# STM32MP23_CM33 register map
File version: 1.2
CPU: CM33 r0p1, little endian, MPU, FPU, vendor SysTick, 8 interrupt priority bits
Registers are 32-bit, read-write, reset 0x0 unless marked. A register's access mark holds for its fields unless they carry their own. Offsets are from the block's base; [hi:lo] are bit positions.

## USB3DR (part 1 of 4) — USB3DR register block
Base 0x48300000
Same registers: USB3DR_S 0x58300000
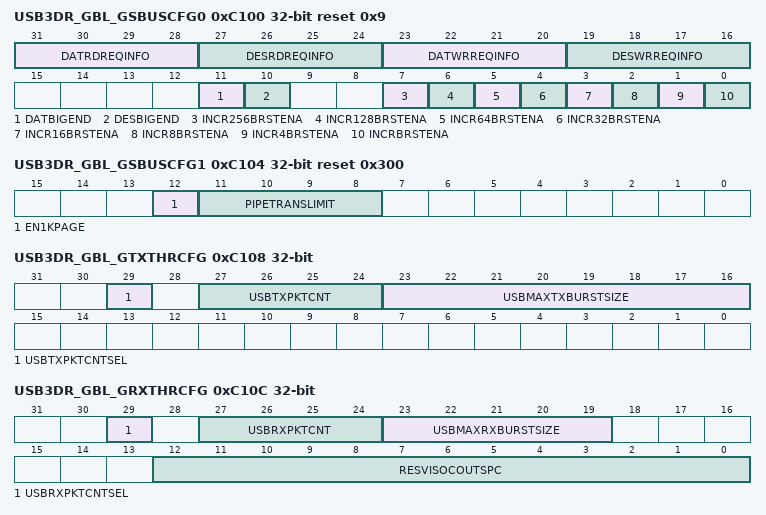
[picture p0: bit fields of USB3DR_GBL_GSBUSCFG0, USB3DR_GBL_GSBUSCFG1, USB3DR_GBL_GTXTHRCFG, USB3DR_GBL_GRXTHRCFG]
0xC100 USB3DR_GBL_GSBUSCFG0 reset 0x9 — USB3DR global device bus configuration register 0
  [31:28] DATRDREQINFO — AHB-prot/AXI-cache/OCP-ReqInfo for data read (DatRdReqInfo) Input to BUS-GM.
  [27:24] DESRDREQINFO — AHB-prot/AXI-cache/OCP-ReqInfo for descriptor read (DesRdReqInfo) Input to BUS-GM.
  [23:20] DATWRREQINFO — AHB-prot/AXI-cache/OCP-ReqInfo for data write (DatWrReqInfo) Input to BUS-GM.
  [19:16] DESWRREQINFO — AHB-prot/AXI-cache/OCP-ReqInfo for descriptor write (DesWrReqInfo). Input to BUS-GM.
  [11] DATBIGEND — Data access is big endian This bit controls the endian mode for data accesses. In big endian mode, both read and write DMA accesses for packet data use a Byte Invariant Big-Endian mode. Note: Since AXI requires byte invariant endianness, setting DescBigend and DatBigEnd to one causes an address invariant transform to be applied, which is not appropriate. See [AXI]. Hence for an AXI master (USB3DR_MBUS_TYPE=1), this bit must be set to zero.
    0=Little endian; 1=Big endian
  [10] DESBIGEND — Descriptor access is big endian This bit controls the endian mode for descriptor accesses. In big endian mode, both read and write DMA accesses for descriptors use a Byte Invariant Big-Endian mode. in the following cases, data are considered as 'embedded data' in the descriptors: Device mode: the buffer pointer of a setup TRB points to the setup TRB itself. Host mode: the immediate data (IDT) bit in a transfer TRB is set to 1. In device mode, if the system uses different endian modes for descriptor and data, software must not use 'embedded' data. In host mode, if the system uses different endian modes for data and descriptors, the controller treats 'embedded data' as descriptor (not as data) in terms of endian mode handling. If this is not the expectation of the system, the software must manipulate the 'embedded data' accordingly. Note: Since AXI requires byte invariant endianness, setting DescBigend and DatBigEnd to 1 causes an address invariant transform to be applied, which is not appropriate. See [AXI]. Hence for an AXI master (USB3DR_MBUS_TYPE=1), this bit must be set to zero.
    0=little endian; 1=big endian
  [7] INCR256BRSTENA — INCR256 burst type enable Input to BUS-GM. For the AHB/AXI configuration, if software sets this bit to 1, the AHB/AXI master uses INCR to do the 256-beat burst.
  [6] INCR128BRSTENA — INCR128 burst type enable Input to BUS-GM; For the AHB/AXI configuration, if software sets this bit to 1, the AHB/AXI master uses INCR to do the 128-beat burst.
  [5] INCR64BRSTENA — INCR64 burst type enable Input to BUS-GM. For the AHB/AXI configuration, if software sets this bit to 1, the AHB/AXI master uses INCR to do the 64-beat burst.
  [4] INCR32BRSTENA — INCR32 burst type enable Input to BUS-GM. For the AHB/AXI configuration, if software sets this bit to 1, the AHB/AXI master uses INCR to do the 32-beat burst.
  [3] INCR16BRSTENA — INCR16 burst type enable Input to BUS-GM. For the AHB/AXI configuration, if software sets this bit to 1, the AHB/AXI master uses INCR to do the 16-beat burst.
  [2] INCR8BRSTENA — INCR8 burst type enable Input to BUS-GM. For the AHB/AXI configuration, if software sets this bit to 1, the AHB/AXI master uses INCR to do the 8-beat burst.
  [1] INCR4BRSTENA — INCR4 burst type enable Input to BUS-GM. For the AXI configuration, when this bit is enabled the controller is allowed to do bursts of beat length 1, 2, 3, and 4. It is highly recommended that this bit is enabled to prevent descriptor reads and writes from being broken up into separate transfers.
  [0] INCRBRSTENA — Undefined length INCR burst type enable (INCRBrstEna) Input to BUS-GM This bit determines the set of burst lengths the master interface uses. It works in conjunction with GSBUSCFG0[7:1] (INCR256/128/64/32/16/8/4). HBURST (for AHB configurations) and ARLEN/AWLEN (for AXI configurations) do not use INCR except in case of non-aligned burst transfers. In the case of address-aligned transfers, they use only the following burst lengths: 1 4 (if GSBUSCFG0.INCR4BrstEna=1) 8 (if GSBUSCFG0.INCR8BrstEna=1) 16 (if GSBUSCFG0.INCR16BrstEna=1) 32 (if GSBUSCFG0.INCR32BrstEna=1) 64 (if GSBUSCFG0.INCR64BrstEna=1) 128 (if GSBUSCFG0.INCR128BrstEna=1) 256 (if GSBUSCFG0.INCR256BrstEna=1) Note: In case of non-address-aligned transfers, INCR may get generated at the beginning and end of the transfers to align the address boundaries, even though INCR is disabled. Note: In AHB mode, if INCRX burst mode is enabled, but none of the supported INCRx bursts bits are enabled, then the controller performs (undefined length) INCR bursts. AHB configurations: HBURST uses SINGLE or INCR of any length with handling 1KB boundary breakup. AXI configurations: ARLEN/AWLEN uses any length less than or equal to the largest-enabled burst length of INCR32/64/128/256. For cache line-aligned applications, this bit is typically set to 0 to ensure that the master interface uses only power-of-2 burst lengths (as enabled via GSBUSCFG0[7:0]).
    0=INCRX burst mode; 1=INCR (undefined length) burst mode
0xC104 USB3DR_GBL_GSBUSCFG1 reset 0x300 — USB3DR global bus configuration register 1
  [12] EN1KPAGE — 1K page boundary enable By default (this bit is disabled) the AXI breaks transfers at the 4K page boundary. When this bit is enabled, the AXI master (DMA data) breaks transfers at the 1K page boundary.
  [11:8] PIPETRANSLIMIT — AXI pipelined transfers burst request limit The field controls the number of outstanding pipelined transfer requests the AXI master pushes to the AXI slave. When the AXI master reaches this limit, it does not make any more requests on the AXI ARADDR and AWADDR buses until the associated data phases complete. This field is encoded as follows: ...
    0=1 request; 1=2 requests; 2=3 requests; 3=4 requests; 15=16 requests
0xC108 USB3DR_GBL_GTXTHRCFG — USB3DR global TX threshold control register
  [29] USBTXPKTCNTSEL — USB transmit packet count enable This field enables/disables the USB transmission multi-packet thresholding:
    0=USB transmission multi-packet thresholding is disabled. The core can start transmission on the USB after the entire (one full) packet has been fetched into the corresponding TXFIFO.; 1=USB transmission multi-packet thresholding is enabled. The core can only start transmission on the USB after USB transmit packet count amount of packets for the USB transaction (burst) are already in the corresponding TXFIFO. This mode is valid in both host and device modes. It is only used for SuperSpeed operation.
  [27:24] USBTXPKTCNT — USB transmit packet count This field specifies the number of packets that must be in the TXFIFO before the core can start transmission for the corresponding USB transaction (burst). This field is only valid when the USB transmit packet count enable field is set to one. Valid values are from 1 to 15. Note: In device mode, if device controller does not have the TRBs for the number of packets or if it cannot fetch the TRBs because of high latency or switching between other endpoints, then it does not wait for the threshold number of packets. The threshold number of packets is honored only when the TRBs are available in the controller for the number of packets before it starts the data fetch. This field must be less than or equal to the USB maximum TX burst size field.
  [23:16] USBMAXTXBURSTSIZE — USB maximum TX burst size When UsbTxPktCntSel is 1, this field specifies the maximum bulk OUT burst the core can do. When the system bus is slower than the USB, TX FIFO can underrun during a long burst. User can program a smaller value to this field to limit the TX burst size that the core can do. Host mode: It only applies to SS bulk, isochronous, and Interrupt OUT endpoints. Device mode: This value is not used in device mode, but users need to program a value when using the TX threshold feature to make sure that the value programmed in UsbTxPktCnt is less than this value. Valid values are from 1 to 16.
0xC10C USB3DR_GBL_GRXTHRCFG — USB3DR global RX threshold control register
  [29] USBRXPKTCNTSEL — USB receive packet count enable This field enables/disables the USB reception multi-packet thresholding: In device mode, Setting this bit to 1 also enables the functionality of reporting NUMP in the ACK TP based on the RX FIFO space instead of reporting a fixed NUMP derived from DCFG.NUMP for non-control endpoints. If external buffer control (EBC) feature is used, disable this mode by setting UsbRxPktCntSel to 0.
    0=The core can only start reception on the USB when the RX FIFO has space for at least one packet; 1=The core can only start reception on the USB when the RX FIFO has space for at least UsbRxPktCnt amount of packets. This mode is valid in both host and device modes. It is only used for SuperSpeed.
  [27:24] USBRXPKTCNT — USB receive packet count In host mode, this field specifies the space (in terms of number of packets) that must be available in the RX FIFO before the core can start the corresponding USB RX transaction (burst). In device mode, this field specifies the space (in terms of number of packets) that must be available in the RX FIFO before the core can send ERDY for a flow-controlled endpoint. This field is valid only when the USB receive packet count enable field is set to 1. The valid values for this field are from 1 to 15. Note: This field must be less than or equal to the USB maximum receive burst size field.
  [23:19] USBMAXRXBURSTSIZE — USB maximum receive burst size In host mode, this field specifies the maximum bulk IN burst the USB3DR can perform. When the system bus is slower than the USB, RX FIFO can overrun during a long burst. A smaller value can be programmed to this field to limit the RX burst size that the core can perform. It only applies to SS bulk, isochronous, and interrupt IN endpoints in the host mode. In device mode, this field specifies the NUMP value that is sent in ERDY for an OUT endpoint. The programmed value should not exceed the RXFIFO size. This field is valid only when UsbRxPktCntSel is one. The valid values for this field are from 1 to 16.
  [12:0] RESVISOCOUTSPC — Space reserved in RX FIFO for ISOC OUT In host mode, this field is not applicable and must be programmed to 0. In device mode, this value represents the amount of space to be reserved for ISOC OUT packets. The value to be programmed should be chosen so as to ensure that non ISOC packets are not completely dropped. If no space needs to be reserved for ISOC OUT packets, program this field to 0. This field is valid only in device mode. The maximum configurable depth of RX FIFO is 8192. Therefore, this field is 13 bits wide. The value of space reserved is in terms of USB3DR_MDWIDTH. For SS, the space reservation is always rounded off to the nearest packet boundary. Therefore, it is always recommended to program a value corresponding to MPS or its multiples. For HS/FS, the space reservation is the actual value. Note: For SS, reserve space for ISOC when the RX FIFO space can accommodate two MPS or more. Otherwise, this may result in degraded performance for non-ISOC packets. If the space is entirely allocated for ISOC, the non-ISOC packets are completely dropped.
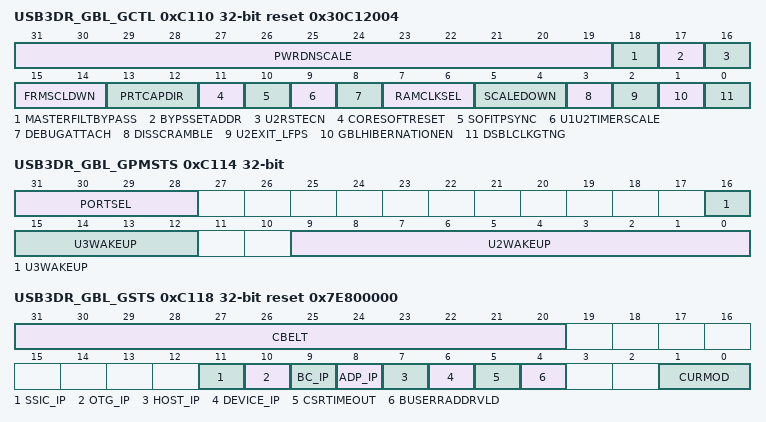
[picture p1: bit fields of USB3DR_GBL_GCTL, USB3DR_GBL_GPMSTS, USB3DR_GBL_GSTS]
0xC110 USB3DR_GBL_GCTL reset 0x30C12004 — USB3DR global control register
  [31:19] PWRDNSCALE — Power down scale (PwrDnScale) The USB3 suspend_clk input replaces pipe3_rx_pclk as a clock source to a small part of the USB3 core that operates when the SS PHY is in its lowest power (P3) state, and therefore does not provide a clock. The power down scale field specifies how many suspend_clk periods fit into a 16kHz clock period. When performing the division, round up the remainder. For example, when using an 8-bit/16-bit/32-bit PHY and 25MHz suspend clock, Power Down scale=25000kHz/16kHz=1563 (rounded up) Minimum suspend clock frequency is 32kHz Note: Maximum suspend clock frequency is 125MHz The LTSSM uses suspend clock for 12ms and 100ms timers during suspend mode. According to the USB 3.0 specification, the accuracy on these timers is 0% to +50%. 12ms + 0~+50% accuracy=18ms (Range is 12ms - 18ms) 100ms + 0~+50% accuracy=150ms (Range is 100ms - 150ms). The suspend clock accuracy requirement is: (12,000/62.5) (GCTL[31:19]) actual suspend_clk_period, must be between 12,000 and 18,000 (100,0000/62.5) (GCTL[31:19]) actual suspend_clk_period, must be between 100,000 and 150,000 For example, if suspend_clk frequency varies from 7.5MHz to 10.5MHz, then the value that needs to be programmed is: Power down scale=10500/16=657 (rounded up integer).
  [18] MASTERFILTBYPASS — Master filter bypass
    0=Filters enabled; 1=All VBUS debouncing filters are bypassed, regardless of the USB3DR_EN_BUS_FILTERS value. The double synchronizers to mac_clk preceding the filters are also bypassed.
  [17] BYPSSETADDR — Bypass SetAddress in Device mode When BYPSSETADDR bit is set, the device core uses the value in the DCFG[DevAddr] bits directly for comparing the device address in the tokens. This feature can be used in simulation to avoid sending an actual SET ADDRESS control transfer on the USB, and make the device core respond to a new address. When the xHCI debug capability is enabled and this bit is set, the debug target immediately enters the configured state without requiring the debug Host to send a SetAddress or SetConfig request. Note: This bit can be set for simulation purposes only. In the actual hardware, this bit must be set to 0.
  [16] U2RSTECN — U2RSTECN If the SuperSpeed connection fails during POLL or LMP exchange, the device connects at non-SS mode. If this bit is set, then the device attempts three more times to connect at SS, even if it previously failed to operate in SS mode. For each attempt, the device checks receiver termination eight times. From 2.60a release, this bit controls whether to check for RX.Detect eight times or one time for every attempt. The device controller on USB 2.0 reset checks for receiver termination eight times per attempt if this bit is set to zero, or only once per attempt if the bit is set to one. Note: This bit is applicable only in Device mode.
  [15:14] FRMSCLDWN — FRMSCLDWN This field scales down device view of a SOF/USOF/ITP duration. When xHCI debug capability is enabled, this field also scales down the MaxPacketSize of the IN and OUT bulk endpoint to allow more traffic during simulation. It can only be changed from a non-zero value during simulation.
    1=B_0x1_SS_HS_MODE_ (implements interval to be 62.5 us); 0=B_0x0_SS_HS_MODE_ (implements interval to be 125 us)
  [13:12] PRTCAPDIR — Port capability direction (PrtCapDir) When USB3DR_EN_OTG is 0, then the core acts as a DRD. When USB3DR_EN_OTG is 1: If PrtCapDir is 0b11, it acts as an OTG 2.0 device with A-device or B-device determined by the IDDIG input, and Host or Peripheral role based on HNP. If PrtCapDir is 0b01, it acts as a DRD in Host mode. If PrtCapDir is 0b10, it acts as a DRD in Device mode. The OTG device can be programmed to enable/disable SRP and HNP by using the fields present in OCFG register. When USB3DR_EN_OTG is 2: If PrtCapDir is 0b11, it acts as an OTG 3.0 device with A-device or B-device determined by the IDDIG input, and Host or Peripheral role based on HNP/RSP. If PrtCapDir is 0b01, it acts as a DRD in Host mode. In this mode, the VBUS is driven immediately after power-on reset. When the USB3DR controller is plugged into a PC and the application configures the device later on, VBUS is driven on the USB from both sides of the cable. This may damage the PC host. If PrtCapDir is 0b10, it acts as a DRD in Device mode. The OTG device can be programmed to enable/disable SRP and HNP/RSP using the fields present in the OCFG register. Note: For static Host-only/Device-only applications, use DRD Host or DRD Device mode. The combination of GCTL.PrtCapDir=0b11 with SRP and HNP/RSP disabled is not recommended for these applications. The sequence for switching modes in DRD configuration is as follows: Switching from Device to Host: 1. Reset the controller using GCTL[11] (CoreSoftReset). 2. Set GCTL[13:12] (PrtCapDir) to 0b01 (Host mode). 3. Reset the host using USBCMD.HCRESET. 4. Initialize the Host registers. Switching from Host to Device: 1. Reset the controller using GCTL[11] (CoreSoftReset). 2. Set GCTL[13:12] (PrtCapDir) to 0b10 (Device mode). 3. Reset the device by setting DCTL[30] (CSftRst). 4. Initialize the Device registers. Programming this field with random data causes the core to keep toggling between the host mode and the device mode. Bit bash register testing is not recommended.
    1=for Host configurations; 2=for Device configurations; 3=for OTG configurations
  [11] CORESOFTRESET — Core soft reset (CoreSoftReset) Clears the interrupts and all the CSRs except the following registers: - GCTL - GUCTL - GSTS - GSNPSID - GGPIO - GUID - GUSB2PHYCFGn registers - GUSB3PIPECTLn registers - DCFG - DCTL - DEVTEN - DSTS When reseting PHYs (using GUBS3PHYCFG or GUSB3PIPECTL registers), the core must be kept in reset state until PHY clocks are stable. This controls the bus, ram, and MAC domain resets. Note: This bit is for debug purposes only. Use USBCMD.HCRESET in xHCI mode and DCTL.SoftReset in device mode for soft reset. Note: Programming this field with random data resets the internal logic of the host controller. Due to this side effect bit bash register testing is not recommended.
    0=No soft reset; 1=Soft reset to core
  [10] SOFITPSYNC — SOFITPSYNC If this bit is set to 0 operating in host mode, the core keeps the UTMI/ULPI PHY on the first port in a non-suspended state whenever there is a SuperSpeed port that is not in RX.Detect, SS.Disable and U3. If this bit is set to '1' operating in host mode, the core keeps the UTMI/ULPI PHY on the first port in a non-suspended state whenever the other non-SuperSpeed ports are not in a suspended state. This feature is useful because it saves power by suspending UTMI/ULPI when SuperSpeed only is active, and it helps resolve when the PHY does not transmit a host resume unless it is placed in suspend state. This bit must be programmed as a part of initialization at power-on reset, and must not be dynamically changed afterwards. Note: USB2PHYCFGn[6].PhySusp eventually decides to put the UTMI/ULPI PHY into suspend state. In addition, when this bit is set to 1, the core generates ITP from the ref_clk based counter. Otherwise, ITP and SOF are generated from utmi/ulpi_clk[0] based counter. To program the reference clock period inside the core, refer to GUCTL[31:22].REFCLKPER. Note: This feature is valid in Host and DRD/OTG configurations and used only in Host mode operation. Note: If this feature or the GFLADJ.GFLADJ_REFCLK_LPM_SEL is never used, the minimum frequency for the ref_clk can be as low as 32kHz. The suspend_clk (as low as 32kHz) can be connected to the ref_clk. Note: If hardware-based LPM or software-based LPM has to be enabled (PORTPMSC.HLE=1), then this feature cannot be used. Turn off this feature by setting this bit to 0 and use the GFLADJ.GFLADJ_REFCLK_LPM_SEL feature. Note: If this bit is set to 1, the GUSB2PHYCFG.U2_FREECLK_EXISTS bit and the USB3DR_FREECLK_USB2_EXIST parameter must be set to 0. Program this bit to 0 if the core is intended to be operated in USB 3.0 mode.
  [9] U1U2TIMERSCALE — Disable U1/U2 timer scaledown (U1U2TimerScale) If set to 1 along with GCTL[5:4] (ScaleDown)=0bx1, disables the scale down of U1/U2 inactive timer values. This is for simulation mode only.
  [8] DEBUGATTACH — Debug attach When this bit is set, SS link proceeds directly to the polling link state (after RUN/STOP in the DCTL register is asserted) without checking remote termination; Link LFPS polling timeout is infinite; Polling timeout during TS1 is infinite (in case link is waiting for TXEQ to finish).
  [7:6] RAMCLKSEL — RAM clock select (RAMClkSel) In Device mode, upon a USB reset and USB disconnect, the hardware clears these bits to 00. Note: In device mode, if RAMClkSel is set to 0b11 (mac2_clk), the controller internally switches the ram_clk to bus_clk when the link state changes to suspend (L2 or L3), and switches the ram_clk back to mac2_clk when the link state changes to resume or U2. Note: In host mode, if a value of 2/3 is chosen, then controller switches ram_clk between bus_clk, mac2_clk and pipe_clk, pipe_clk/2, based on the state of the U2/U3 ports. For example if only the U2 port is active and the U3 ports are suspended, then the ram_clk is swicthed to mac2_clk. When only the U3 ports are active and the U2 ports are suspended, then the core internally swicth the ram_clk to pipe3 clock and when all U2 and U3 ports are suspended, it switches the ram_clk to bus_clk. This allows decoupling the ram_clk from the bus_clk and depending on the bandwidth requirement allows the bus_clk to be run at a lower frequency than the ram_clk requirements. bus_clk frequency still cannot go below 60MHz in Host mode, and this is not verified. Note: A value of 2 can be chosen only if the pipe data width is 8 or 16 bits. In this case when the ram_clk is switched to pipe_clk, it uses pipe_clk/2 instead of pipe_clk. If a value of 3 is chosen for RAMClkSel, when ram_clk is switched to pipe_clk, then pipe_clk is used without any divider. Note: In device mode, when RAMClkSel different 0b00, the bus_clk_early frequency can be a minimum of 1 MHz. This is tested in simulation and also in hardware with Linux, Microsoftsup®/sup Windowssup®/sup 8, and MCCI Windowssup®/sup 7 host drivers. Only control and non-periodic transfers are supported when bus_clk is 1 MHz. For periodic applications, the bus_clk_early minimum frequency is higher depending on the application and device bus. Even though 1 MHz has been tested with standard host drivers, Synopsys recommends 5 MHz minimum for ASIC designs to provide a margin or at least have a backup option to increase the bus_clk frequency to 5 MHz if needed. Programming this field with random data causes side effect. Bit bash register testing is not recommended.
    0=Bus clock; 1=Pipe clock (only used in Device mode); 2=In Device mode, pipe/2 clock. In Host mode, controller switches ram_clk between pipe/2 clock, mac2_clk and bus_clk based on the status of the U2/U3 ports; 3=In device mode, selects mac2_clk as ram_clk (when 8-bit UTMI or ULPI used, not supported in 16-bit UTMI mode). In Host mode, controller switches ram_clk between pipe_clk, mac2_clk and bus_clk based on the status of the U2/U3 ports.
  [5:4] SCALEDOWN — Scale-down mode (ScaleDown) When scale-down mode is enabled for simulation, the core uses scaled-down timing values, resulting in faster simulations. When scale-down mode is disabled, actual timing values are used. This is required for hardware operation. Number of TxEq training sequences reduce to 8 LFPS polling burst time reduce to 256ns LFPS warm reset receive reduce to 30 us.
    0=B_0x0_HS_FS_LS_MODES (Disables all scale-downs. Actual timing values are used.); 1=B_0x1_HS_FS_LS_MODES (Enables scale-down of all timing values except Device mode suspend and resume. These include speed enumeration, HNP/SRP, and Host mode suspend and resume.); 2=B_0x2_HS_FS_LS_MODES (Enables scale-down of Device mode suspend and resume timing values only.); 3=B_0x3_HS_FS_LS_MODES (Enables bit 0 and bit 1 scale-down timing values.)
  [3] DISSCRAMBLE — Disable scrambling (DisScramble) Transmit request to link partner on next transition to recovery or polling.
  [2] U2EXIT_LFPS — U2EXIT_LFPS If this bit is, This bit is added to improve interoperability with a third-party host/device controller. This host/device controller in U2 state while performing receiver detection generates an LFPS glitch of about 4ms duration. This causes the host/device to exit from U2 state because the LFPS filter value is 248ns. With the new functionality enabled, the host/device can stay in U2 while ignoring this glitch from the host/device controller. This bit is applicable for both host and device controller. This bit is added to improve interoperability with a third party host controller. This host controller in U2 state while performing receiver detection generates an LFPS glitch of about 4ms duration. This causes the device to exit from U2 state because the LFPS filter value is 248ns. With the new functionality enabled, the device can stay in U2 while ignoring this glitch from the host controller.
    0=the link treats 248ns LFPS as a valid U2 exit; 1=the link waits for 8 us of LFPS before it detects a valid U2 exit
  [1] GBLHIBERNATIONEN ro — GblHibernationEn This bit enables hibernation at the global level. If hibernation is not enabled through this bit, the PMU immediately accepts the D0 → D3 and D3 → D0 power state change requests, but does not save or restore any core state. In addition, the PMUs never drive the PHY interfaces and let the core continue to drive the PHY interfaces.
  [0] DSBLCLKGTNG — Disable clock gating (DsblClkGtng) This bit is set to 1 and the core is in Low Power mode, internal clock gating is disabled. This bit can be set to 1 after power-on reset.
0xC114 USB3DR_GBL_GPMSTS (reset mask 0xFFE0C00) — USB3DR global power management status register
  [31:28] PORTSEL wo — Global power management status register, PortSel This field selects the port number.
  [16:12] U3WAKEUP ro — U3Wakeup This field gives the following USB 3.0 port wakeup conditions: xxxx1: Overcurrent detected xxx1x: Resume detected xx1xx: Connect detected x1xxx: Disconnect detected 1xxxx: Last connection state
  [9:0] U2WAKEUP ro — U2Wakeup This field indicates the following USB 2.0 port wakeup conditions: xxxxxxxxx1: Overcurrent detected xxxxxxxx1x: Resume detected xxxxxxx1xx: Connect detected xxxxxx1xxx: Disconnect detected xxxxx1xxxx: Last connection state xxxx1xxxxx: ID change detected xxx1xxxxxx: SRP request detected xx1xxxxxxx: ULPI interrupt detected x1xxxxxxxx: USB Reset detected 1xxxxxxxxx: Resume detected changed
0xC118 USB3DR_GBL_GSTS reset 0x7E800000 — USB3DR global status register
  [31:20] CBELT ro — Current BELT value In Host mode, this field indicates the minimum value of all received device BELT values and the BELT value that is set by the set latency tolerance value command.
  [11] SSIC_IP ro — SSIC interrupt pending (SSIC_IP) This field indicates that there is a pending interrupt related to SSIC in the SEVT register. Note: When the USB3DR_NUM_SSIC_PORTS parameter is set to zero, this bit is reserved.
  [10] OTG_IP ro — OTG interrupt pending This field indicates that there is a pending interrupt pertaining to OTG in OEVT register.
  [9] BC_IP ro — Battery charger interrupt pending This field indicates that there is a pending interrupt pertaining to BC in BCEVT register.
  [8] ADP_IP ro — ADP interrupt pending This field indicates that there is a pending interrupt pertaining to ADP in ADPEVT register.
  [7] HOST_IP ro — Host interrupt pending: This field indicates that there is a pending interrupt pertaining to xHC in the Host event queue.
  [6] DEVICE_IP ro — Device interrupt pending This field indicates that there is a pending interrupt pertaining to peripheral (device) operation in the Device event queue.
  [5] CSRTIMEOUT — CSR timeout When this bit is 1, it indicates that the software performed a write or read to a core register that cannot be completed within USB3DR_CSR_ACCESS_TIMEOUT bus clock cycles (default: 0x1FFFF).
  [4] BUSERRADDRVLD — Bus error address valid (BusErrAddrVld) Indicates that the GBUSERRADDR register is valid and reports the first bus address that encounters a bus error. Note: Only supported in AHB and AXI configurations.
  [1:0] CURMOD ro — Current mode of operation (CurMod) Indicates the current mode of operation: Others: Reserved
    0=Device mode; 1=Host mode
